# ATA664251 device description
Architecture: AVR8; Family: tinyAVR
Registers are 8-bit, access not given, no defined reset value unless marked. A register's access mark holds for its fields unless they carry their own. Offsets are from the block's base; [hi:lo] are bit positions; {n}, {i} and the like mark numbered series.

## WDT — Watchdog Timer
Instances: WDT 0x00
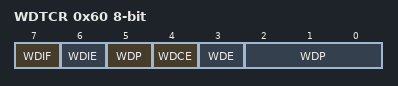
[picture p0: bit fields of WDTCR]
0x60 WDTCR — Watchdog Timer Control Register
  [7] WDIF — Watchdog Timeout Interrupt Flag
  [6] WDIE — Watchdog Timeout Interrupt Enable
  [4] WDCE — Watchdog Change Enable
  [3] WDE — Watch Dog Enable
  [5,2:0] WDP — Watchdog Timer Prescaler Bits
    0=Oscillator Cycles 2K; 1=Oscillator Cycles 4K; 2=Oscillator Cycles 8K; 3=Oscillator Cycles 16K; 4=Oscillator Cycles 32K; 5=Oscillator Cycles 64K; 6=Oscillator Cycles 128K; 7=Oscillator Cycles 256K; 8=Oscillator Cycles 512K; 9=Oscillator Cycles 1024K

## EEPROM
Instances: EEPROM 0x00
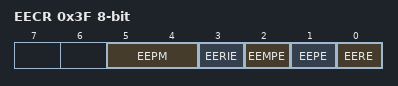
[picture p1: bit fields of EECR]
0x3F EECR — EEPROM Control Register
  [5:4] EEPM — EEPROM Programming Mode Bits
    0=Erase and Write in one operation; 1=Erase Only; 2=Write Only
  [3] EERIE — EEPROM Ready Interrupt Enable
  [2] EEMPE — EEPROM Master Write Enable
  [1] EEPE — EEPROM Write Enable
  [0] EERE — EEPROM Read Enable
0x40 EEDR — EEPROM Data Register
  [7:0] EEDR — EEPROM Data Register Bits
0x41 EEAR 16-bit bits used 8:0 — EEPROM Address Register Bytes

## SPI
Instances: SPI 0x00
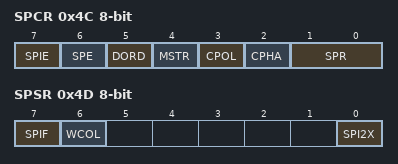
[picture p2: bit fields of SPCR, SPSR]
0x4C SPCR — SPI Control Register
  [7] SPIE — SPI Interrupt Enable
  [6] SPE — SPI Enable
  [5] DORD — Data Order
  [4] MSTR — Master/Slave Select
  [3] CPOL — Clock polarity
  [2] CPHA — Clock Phase
  [1:0] SPR — SPI Clock Rate Selects
    0=fosc/4; 1=fosc/16; 2=fosc/64; 3=fosc/128; 4=fosc/2; 5=fosc/8; 6=fosc/32; 7=fosc/64
0x4D SPSR — SPI Status Register
  [7] SPIF — SPI Interrupt Flag
  [6] WCOL — Write Collision Flag
  [0] SPI2X — Double SPI Speed Bit
0x4E SPDR — SPI Data Register
  [7:0] SPDR — SPI Data Register bits

## AD_CONVERTER
Instances: AD_CONVERTER 0x00
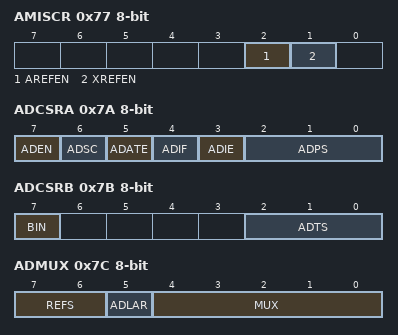
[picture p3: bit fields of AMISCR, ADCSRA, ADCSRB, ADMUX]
0x77 AMISCR — Analog Miscellaneous Control Register (Shared with CURRENT_SOURCE IO_MODULE)
  [2] AREFEN — External Voltage Reference Input Enable
  [1] XREFEN — Internal Voltage Reference Output Enable
0x78 ADC 16-bit — ADC Data Register Bytes
0x7A ADCSRA — The ADC Control and Status register A
  [7] ADEN — ADC Enable
  [6] ADSC — ADC Start Conversion
  [5] ADATE — ADC Auto Trigger Enable
  [4] ADIF — ADC Interrupt Flag
  [3] ADIE — ADC Interrupt Enable
  [2:0] ADPS — ADC Prescaler Select Bits
    0=2; 1=2; 2=4; 3=8; 4=16; 5=32; 6=64; 7=128
0x7B ADCSRB — The ADC Control and Status register B (Shared with ANALOG_COMPARATOR IO_MODULE)
  [7] BIN — Bipolar Input Mode
  [2:0] ADTS — ADC Auto Trigger Source bits
    0=Free Running mode; 1=Analog Comparator; 2=External Interrupt Request 0; 3=Timer/Counter1 Compare Match A; 4=Timer/Counter1 Overflow; 5=Timer/Counter1 Compare Match B; 6=Timer/Counter1 Capture Event; 7=Watchdog Interrupt Request
0x7C ADMUX — The ADC multiplexer Selection Register
  [7:6] REFS — Reference Selection Bits
    0=If AREFEN==0 then Internal AVCC as Voltage Reference. If AREFEN==1 then AREF pin as Voltage Reference.; 1=If AREFEN==0 then Internal 1.1V as Voltage Reference without external capacitor. If AREFEN==1 then Internal 1.1V as Voltage Reference with external capacitor at AREF pin.; 2=If AREFEN==0 then Internal AVCC as Voltage Reference. If AREFEN==1 then AREF pin as Voltage Reference.; 3=If AREFEN==0 then Internal 2.56V as Voltage Reference without external capacitor. If AREFEN==1 then Internal 2.56V as Voltage Reference with external capacitor at AREF pin.
  [5] ADLAR — Left Adjust Result
  [4:0] MUX — Analog Channel and Gain Selection Bits
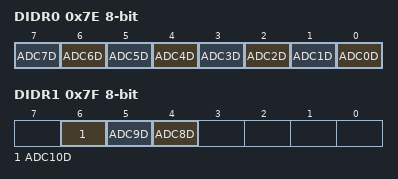
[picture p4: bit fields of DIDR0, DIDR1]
0x7E DIDR0 — Digital Input Disable Register 0
  [n] ADC{n}D (n=0..7)
0x7F DIDR1 — Digital Input Disable Register 1
  [6] ADC10D, [5] ADC9D, [4] ADC8D

## CURRENT_SOURCE
Instances: CURRENT_SOURCE 0x00
0x77 AMISCR — Analog Miscellaneous Control Register (Shared with AD_CONVERTER IO_MODULE)
  [0] ISRCEN — Current Source Enable
